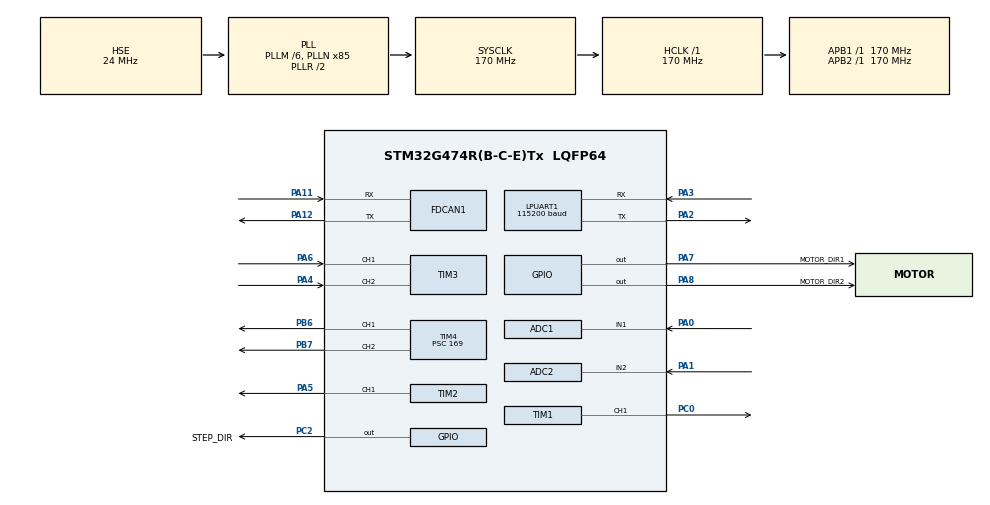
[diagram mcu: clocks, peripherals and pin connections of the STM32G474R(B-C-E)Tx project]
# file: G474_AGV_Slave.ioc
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ADC1.Channel-0\#ChannelRegularConversion=ADC_CHANNEL_1
ADC1.DMAContinuousRequests=ENABLE
ADC1.ExternalTrigConv=ADC_EXTERNALTRIG_T6_TRGO
ADC1.NbrOfConversionFlag=1
ADC1.OffsetNumber-0\#ChannelRegularConversion=ADC_OFFSET_NONE
ADC1.Rank-0\#ChannelRegularConversion=1
ADC1.SamplingTime-0\#ChannelRegularConversion=ADC_SAMPLETIME_6CYCLES_5
ADC1.master=1
ADC2.Channel-0\#ChannelRegularConversion=ADC_CHANNEL_2
ADC2.ContinuousConvMode=DISABLE
ADC2.DMAContinuousRequests=ENABLE
ADC2.ExternalTrigConv=ADC_EXTERNALTRIG_T6_TRGO
ADC2.NbrOfConversionFlag=1
ADC2.OffsetNumber-0\#ChannelRegularConversion=ADC_OFFSET_NONE
ADC2.Rank-0\#ChannelRegularConversion=1
ADC2.SamplingTime-0\#ChannelRegularConversion=ADC_SAMPLETIME_6CYCLES_5
Dma.ADC1.0.Direction=DMA_PERIPH_TO_MEMORY
Dma.ADC1.0.EventEnable=DISABLE
Dma.ADC1.0.Instance=DMA1_Channel1
Dma.ADC1.0.MemDataAlignment=DMA_MDATAALIGN_HALFWORD
Dma.ADC1.0.MemInc=DMA_MINC_ENABLE
Dma.ADC1.0.Mode=DMA_CIRCULAR
Dma.ADC1.0.PeriphDataAlignment=DMA_PDATAALIGN_HALFWORD
Dma.ADC1.0.PeriphInc=DMA_PINC_DISABLE
Dma.ADC1.0.Polarity=HAL_DMAMUX_REQ_GEN_RISING
Dma.ADC1.0.Priority=DMA_PRIORITY_HIGH
Dma.ADC1.0.RequestNumber=1
Dma.ADC1.0.SignalID=NONE
Dma.ADC1.0.SyncEnable=DISABLE
Dma.ADC1.0.SyncPolarity=HAL_DMAMUX_SYNC_NO_EVENT
Dma.ADC1.0.SyncRequestNumber=1
Dma.ADC1.0.SyncSignalID=NONE
Dma.ADC2.1.Direction=DMA_PERIPH_TO_MEMORY
Dma.ADC2.1.EventEnable=DISABLE
Dma.ADC2.1.Instance=DMA1_Channel2
Dma.ADC2.1.MemDataAlignment=DMA_MDATAALIGN_HALFWORD
Dma.ADC2.1.MemInc=DMA_MINC_ENABLE
Dma.ADC2.1.Mode=DMA_CIRCULAR
Dma.ADC2.1.PeriphDataAlignment=DMA_PDATAALIGN_HALFWORD
Dma.ADC2.1.PeriphInc=DMA_PINC_DISABLE
Dma.ADC2.1.Polarity=HAL_DMAMUX_REQ_GEN_RISING
Dma.ADC2.1.Priority=DMA_PRIORITY_HIGH
Dma.ADC2.1.RequestNumber=1
Dma.ADC2.1.SignalID=NONE
Dma.ADC2.1.SyncEnable=DISABLE
Dma.ADC2.1.SyncPolarity=HAL_DMAMUX_SYNC_NO_EVENT
Dma.ADC2.1.SyncRequestNumber=1
Dma.ADC2.1.SyncSignalID=NONE
Dma.Request0=ADC1
Dma.Request1=ADC2
FDCAN1.AutoRetransmission=ENABLE
FDCAN1.CalculateBaudRateNominal=1000000
FDCAN1.CalculateTimeBitNominal=1000
FDCAN1.CalculateTimeQuantumNominal=100.0
FDCAN1.NominalPrescaler=17
FDCAN1.NominalSyncJumpWidth=1
FDCAN1.NominalTimeSeg1=7
FDCAN1.NominalTimeSeg2=2
FDCAN1.StdFiltersNbr=1
LPUART1.BaudRate=115200
Mcu.Family=STM32G4
Mcu.Name=STM32G474R(B-C-E)Tx
Mcu.Package=LQFP64
NVIC.DMA1_Channel1_IRQn=true\:0\:0\:false\:false\:true\:false\:true\:true
NVIC.DMA1_Channel2_IRQn=true\:0\:0\:false\:false\:true\:false\:true\:true
NVIC.FDCAN1_IT0_IRQn=true\:0\:0\:false\:false\:true\:true\:true\:true
NVIC.FDCAN1_IT1_IRQn=true\:0\:0\:false\:false\:true\:true\:true\:true
NVIC.LPUART1_IRQn=true\:15\:0\:true\:false\:true\:true\:true\:true
NVIC.PriorityGroup=NVIC_PRIORITYGROUP_4
NVIC.TIM6_DAC_IRQn=true\:1\:0\:true\:false\:true\:true\:true\:true
PA0.Mode=IN1-Single-Ended
PA0.Signal=ADC1_IN1
PA1.Mode=IN2-Single-Ended
PA1.Signal=ADC2_IN2
PA11.Mode=FDCAN_Activate
PA11.Signal=FDCAN1_RX
PA12.Mode=FDCAN_Activate
PA12.Signal=FDCAN1_TX
PA13.Mode=Serial_Wire
PA13.Signal=SYS_JTMS-SWDIO
PA14.Mode=Serial_Wire
PA14.Signal=SYS_JTCK-SWCLK
PA2.Mode=Asynchronous
PA2.Signal=LPUART1_TX
PA3.Mode=Asynchronous
PA3.Signal=LPUART1_RX
PA4.Signal=S_TIM3_CH2
PA5.Signal=S_TIM2_CH1
PA6.Signal=S_TIM3_CH1
PA7.GPIO_Label=MOTOR_DIR1
PA7.Signal=GPIO_Output
PA8.GPIO_Label=MOTOR_DIR2
PA8.Signal=GPIO_Output
PB6.Signal=S_TIM4_CH1
PB7.Signal=S_TIM4_CH2
PC0.Signal=S_TIM1_CH1
PC2.GPIO_Label=STEP_DIR
PC2.Signal=GPIO_Output
PF0-OSC_IN.Mode=HSE-External-Oscillator
PF0-OSC_IN.Signal=RCC_OSC_IN
PF1-OSC_OUT.Mode=HSE-External-Oscillator
PF1-OSC_OUT.Signal=RCC_OSC_OUT
ProjectManager.HeapSize=0x200
ProjectManager.StackSize=0x400
ProjectManager.TargetToolchain=STM32CubeIDE
RCC.ADC12Freq_Value=170000000
RCC.ADC345Freq_Value=170000000
RCC.AHBFreq_Value=170000000
RCC.APB1Freq_Value=170000000
RCC.APB1TimFreq_Value=170000000
RCC.APB2Freq_Value=170000000
RCC.APB2TimFreq_Value=170000000
RCC.CortexFreq_Value=170000000
RCC.EXTERNAL_CLOCK_VALUE=12288000
RCC.HCLKFreq_Value=170000000
RCC.HSE_VALUE=24000000
RCC.HSI48_VALUE=48000000
RCC.HSI_VALUE=16000000
RCC.LSE_VALUE=32768
RCC.PLLM=RCC_PLLM_DIV6
RCC.PLLN=85
RCC.PLLSourceVirtual=RCC_PLLSOURCE_HSE
RCC.SYSCLKFreq_VALUE=170000000
RCC.SYSCLKSource=RCC_SYSCLKSOURCE_PLLCLK
RCC.USBFreq_Value=170000000
RCC.VCOOutputFreq_Value=340000000
SH.S_TIM1_CH1.0=TIM1_CH1,PWM Generation1 CH1
SH.S_TIM2_CH1.0=TIM2_CH1,PWM Generation1 CH1
SH.S_TIM3_CH1.0=TIM3_CH1,Encoder_Interface
SH.S_TIM3_CH2.0=TIM3_CH2,Encoder_Interface
SH.S_TIM4_CH1.0=TIM4_CH1,PWM Generation1 CH1
SH.S_TIM4_CH2.0=TIM4_CH2,PWM Generation2 CH2
TIM1.AutoReloadPreload=TIM_AUTORELOAD_PRELOAD_ENABLE
TIM1.Channel-PWM\ Generation1\ CH1=TIM_CHANNEL_1
TIM1.PeriodNoDither=999
TIM1.Prescaler=169
TIM2.Channel-PWM\ Generation1\ CH1=TIM_CHANNEL_1
TIM2.PeriodNoDither=999
TIM2.Prescaler=169
TIM3.EncoderMode=TIM_ENCODERMODE_TI12
TIM4.Channel-PWM\ Generation1\ CH1=TIM_CHANNEL_1
TIM4.Channel-PWM\ Generation2\ CH2=TIM_CHANNEL_2
TIM4.PeriodNoDither=19999
TIM4.Prescaler=169
TIM4.PulseNoDither_1=1500
TIM4.PulseNoDither_2=1500
TIM6.PeriodNoDither=999
TIM6.Prescaler=169
TIM6.TIM_MasterOutputTrigger=TIM_TRGO_UPDATE
VP_SYS_VS_DBSignals.Mode=DisableDeadBatterySignals
VP_TIM1_VS_ClockSourceINT.Mode=Internal
VP_TIM2_VS_ClockSourceINT.Mode=Internal
VP_TIM4_VS_ClockSourceINT.Mode=Internal
VP_TIM6_VS_ClockSourceINT.Mode=Enable_Timer
board=custom

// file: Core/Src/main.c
/* USER CODE BEGIN Header */
/**
  ******************************************************************************
  * @file           : main.c
  * @brief          : Main program body
  ******************************************************************************
  * @attention
  *
  * Copyright (c) 2026 STMicroelectronics.
  * All rights reserved.
  *
  * This software is licensed under terms that can be found in the LICENSE file
  * in the root directory of this software component.
  * If no LICENSE file comes with this software, it is provided AS-IS.
  *
  ******************************************************************************
  */
/* USER CODE END Header */
#include "main.h"
#include "adc.h"
#include "dma.h"
#include "fdcan.h"
#include "usart.h"
#include "tim.h"
#include "gpio.h"

/* USER CODE BEGIN Includes */
#include "app_g474.h"
#include <stdio.h>
/* USER CODE END Includes */

void SystemClock_Config(void);

int main(void)
{

  /* MCU Configuration--------------------------------------------------------*/

  /* Reset of all peripherals, Initializes the Flash interface and the Systick. */
  HAL_Init();

  /* Configure the system clock */
  SystemClock_Config();

  /* Initialize all configured peripherals */
  MX_GPIO_Init();
  MX_DMA_Init();
  MX_ADC1_Init();
  MX_ADC2_Init();
  MX_FDCAN1_Init();
  MX_LPUART1_UART_Init();
  MX_TIM1_Init();
  MX_TIM2_Init();
  MX_TIM3_Init();
  MX_TIM4_Init();
  MX_TIM6_Init();
  /* USER CODE BEGIN 2 */
  App_Init();
  /* USER CODE END 2 */

  /* Infinite loop */
  /* USER CODE BEGIN WHILE */
  while (1)
  {
      App_Run();
    /* USER CODE END WHILE */

  }
}

void SystemClock_Config(void)
{
  RCC_OscInitTypeDef RCC_OscInitStruct = {0};
  RCC_ClkInitTypeDef RCC_ClkInitStruct = {0};

  /** Configure the main internal regulator output voltage
  */
  HAL_PWREx_ControlVoltageScaling(PWR_REGULATOR_VOLTAGE_SCALE1_BOOST);

  /** Initializes the RCC Oscillators according to the specified parameters
  * in the RCC_OscInitTypeDef structure.
  */
  RCC_OscInitStruct.OscillatorType = RCC_OSCILLATORTYPE_HSE;
  RCC_OscInitStruct.HSEState = RCC_HSE_ON;
  RCC_OscInitStruct.PLL.PLLState = RCC_PLL_ON;
  RCC_OscInitStruct.PLL.PLLSource = RCC_PLLSOURCE_HSE;
  RCC_OscInitStruct.PLL.PLLM = RCC_PLLM_DIV6;
  RCC_OscInitStruct.PLL.PLLN = 85;
  RCC_OscInitStruct.PLL.PLLP = RCC_PLLP_DIV2;
  RCC_OscInitStruct.PLL.PLLQ = RCC_PLLQ_DIV2;
  RCC_OscInitStruct.PLL.PLLR = RCC_PLLR_DIV2;
  if (HAL_RCC_OscConfig(&RCC_OscInitStruct) != HAL_OK)
  {
    Error_Handler();
  }

  /** Initializes the CPU, AHB and APB buses clocks
  */
  RCC_ClkInitStruct.ClockType = RCC_CLOCKTYPE_HCLK|RCC_CLOCKTYPE_SYSCLK
                              |RCC_CLOCKTYPE_PCLK1|RCC_CLOCKTYPE_PCLK2;
  RCC_ClkInitStruct.SYSCLKSource = RCC_SYSCLKSOURCE_PLLCLK;
  RCC_ClkInitStruct.AHBCLKDivider = RCC_SYSCLK_DIV1;
  RCC_ClkInitStruct.APB1CLKDivider = RCC_HCLK_DIV1;
  RCC_ClkInitStruct.APB2CLKDivider = RCC_HCLK_DIV1;

  if (HAL_RCC_ClockConfig(&RCC_ClkInitStruct, FLASH_LATENCY_4) != HAL_OK)
  {
    Error_Handler();
  }
}

void Error_Handler(void)
{
  __disable_irq();
  while (1)
  {
  }
}
